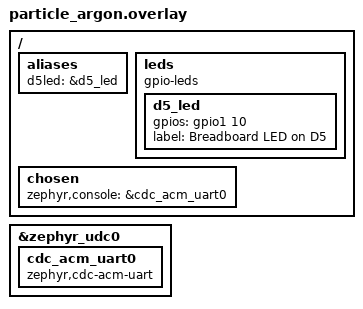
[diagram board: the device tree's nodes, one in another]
/*
 * blank_app board overlay - particle_argon
 *
 * Repoints the console to USB-CDC-ACM - same fix already applied and
 * verified on real hardware for argon_gateway/xenon_sensor/esp32_passthrough
 * (see their own overlays). led1 (the red status LED) is already a
 * mesh_feather.dtsi alias. d5led is the breadboard LED on header D5
 * (nRF P1.10). ACTIVE_HIGH because the other LED leg is on the blue
 * ground rail, so the pin sources current to turn the LED on.
 */

/ {
	aliases {
		d5led = &d5_led;
	};

	leds {
		compatible = "gpio-leds";
		d5_led: d5_led {
			gpios = <&gpio1 10 GPIO_ACTIVE_HIGH>;
			label = "Breadboard LED on D5";
		};
	};

	chosen {
		zephyr,console = &cdc_acm_uart0;
	};
};

&zephyr_udc0 {
	cdc_acm_uart0: cdc_acm_uart0 {
		compatible = "zephyr,cdc-acm-uart";
	};
};
